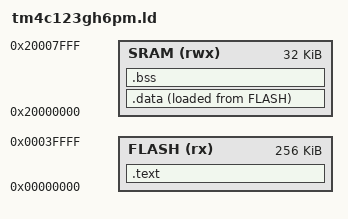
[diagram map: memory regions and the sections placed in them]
MEMORY
{
    FLASH (rx) : ORIGIN = 0x00000000, LENGTH = 256K
    SRAM (rwx) : ORIGIN = 0x20000000, LENGTH = 32K
}

SECTIONS
{
    .text :
    {
        _stext = .;
        KEEP(*(.isr_vector))
        *(.text*)
        *(.rodata*)
        _etext = .;
    } > FLASH

    .data :
    {
        _sdata = .;
        *(.data*)
        _edata = .;
    } > SRAM AT > FLASH

    .bss :
    {
        _sbss = .;
        *(.bss*)
        _ebss = .;
    } > SRAM

    _estack = ORIGIN(SRAM) + LENGTH(SRAM);
}
